# nrf7140_sysctrl register map
Vendor: Nordic Semiconductor; Series: nRF71; File version: 1
Registers are 32-bit, read-write, reset 0x0 unless marked. A register's access mark holds for its fields unless they carry their own. Offsets are from the block's base; [hi:lo] are bit positions; lines under a group give offsets from that group; {n}, {i} and the like mark numbered series.

## PPIB110 — PPIB APB registers 0
Base 0x5F098000
Same registers: PPIB120 0x5F8EE000, PPIB121 0x5F8EF000, PPIB130 0x5F925000, PPIB131 0x5F926000, PPIB132 0x5F98D000, PPIB133 0x5F99D000, PPIB134 0x5F9AD000, PPIB135 0x5F9BD000, PPIB136 0x5F9CD000, PPIB137 0x5F9DD000
{0x0+4i} TASKS_SEND[{i}] (i=0..31) wo — Description collection: This task is unused, but the PPIB provides the SUBSCRIBE task to connect SEND [n] task.
  [0] TASKS_SEND — This task is unused, but the PPIB provides the SUBSCRIBE task to connect SEND [n] task.
    1=Trigger task
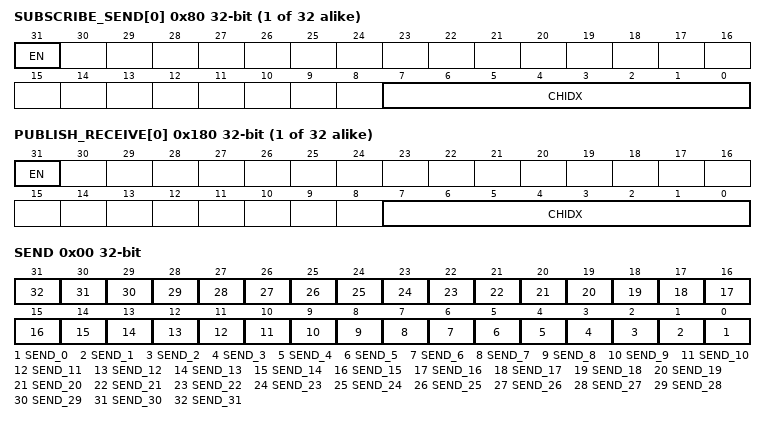
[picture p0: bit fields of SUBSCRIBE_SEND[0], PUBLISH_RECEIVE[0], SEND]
{0x80+4i} SUBSCRIBE_SEND[{i}] (i=0..31) — Description collection: Subscribe configuration for task SEND[n]
  [31] EN
    0=Disabled (Disable subscription); 1=Enabled (Enable subscription)
  [7:0] CHIDX — DPPI channel that task SEND[n] will subscribe to
{0x100+4i} EVENTS_RECEIVE[{i}] (i=0..31) — Description collection: This event is unused, but the PPIB provides the PUBLISH event to connect RECEIVE [n] event.
  [0] EVENTS_RECEIVE — This event is unused, but the PPIB provides the PUBLISH event to connect RECEIVE [n] event.
    0=NotGenerated (Event not generated); 1=Generated (Event generated)
{0x180+4i} PUBLISH_RECEIVE[{i}] (i=0..31) — Description collection: Publish configuration for event RECEIVE[n]
  [31] EN
    0=Disabled (Disable publishing); 1=Enabled (Enable publishing)
  [7:0] CHIDX — DPPI channel that event RECEIVE[n] will publish to
0x400 OVERFLOW group — Unspecified
  0x00 SEND — The task overflow for SEND tasks using SUBSCRIBE_SEND. Write 0 to clear.
    [all] fields
      1=Overflow (Task overflow is happened.); 0=NoOverflow (Task overflow is not happened.)
    [n] SEND_{n} (n=0..31) — The status for tasks overflow at SUBSCRIBE_SEND[{n}].

## ROMC — ROM Controller
Base 0x5F8C6000
0x500 POWER group — Unspecified
  0x00 CONTROL reset 0x1 — ROM power control register.
    [0] MEM0 — Keep the ROM block MEM[0] on or off when in System ON mode.
      0=Off (Power down); 1=On (Power up)

## GLOBAL_MUTEX120 — MUTEX 0
Base 0x4F8D2000
Same registers: GLOBAL_MUTEX130 0x4F927000
{0x400+4i} MUTEX[{i}] (i=0..31) — Description collection: Mutex register
  [0] MUTEX — Mutex register n
    0=Unlocked (Mutex n is in unlocked state); 1=Locked (Mutex n is in locked state)

## GLOBAL_PROTOTYPE — Prototype HW information registers.
Base 0x4F8D2000; alternate view of GLOBAL_MUTEX120
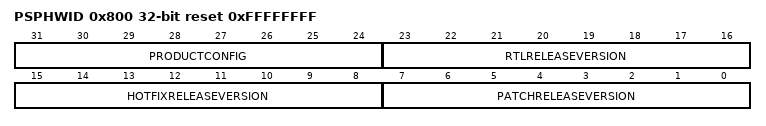
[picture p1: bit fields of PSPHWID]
0x800 PSPHWID ro reset 0xFFFFFFFF — PSP hardware ID register, unique ID for each prototype release. Used to identify RTL release that prototype is based on.
  [31:24] PRODUCTCONFIG
  [23:16] RTLRELEASEVERSION — First letter of RTL release version in ASCII corresponding to A-Z.
  [15:8] HOTFIXRELEASEVERSION
  [7:0] PATCHRELEASEVERSION — PSP patch/bugfix release version
0x804 FPGATIMESTAMP ro — 32-bit timestamp value stored by the FPGA bitstream in format ddddd_MMMM_yyyyyy_hhhhh_mmmmmm_ssssss. Unique for every FPGA netlist implementation, not dependent to RTL synthesis. 0x87654321 set in emulator database.
  [31:0] FPGATIMESTAMP — ddddd = 5 bits to represent 31 days in a month. MMMM = 4 bits to represent 12 months in a year. yyyyyy = 6 bits to represent 0 to 63 (to note year 2000 to 2063). hhhhh = 5 bits to represent 24 hours in a day. mmmmmm = 6 bits to represent 60 minutes in an hour. ssssss = 6 bits to represent 60 seconds in a minute.
0x808 EMULATORSPEEDVALUE ro — Used to store real speed of emulator is running. Used by SW to config UART speed etc, to ensure correct operation.
  [31:0] EMULATORSPEEDVALUE — Actual clock speed for FCLK 400M in emulator (Hz). In FPGA set to 0x0.
0x80C FPGACLOCKDIVIDERRATIO ro — Overall clock divider ratio for FPGA
  [31:0] FPGACLOCKDIVIDERRATIO — Overall clock divider ratio for FPGA. Set to 0 for emulator database.

## Notices in the file
Copyright (c) 2010 - 2024, Nordic Semiconductor ASA
All rights reserved.
Redistribution and use in source and binary forms, with or without modification,
are permitted provided that the following conditions are met:
1. Redistributions of source code must retain the above copyright notice, this
list of conditions and the following disclaimer.
2. Redistributions in binary form, except as embedded into a Nordic
Semiconductor ASA integrated circuit in a product or a software update for
such product, must reproduce the above copyright notice, this list of
conditions and the following disclaimer in the documentation and/or other
materials provided with the distribution.
3. Neither the name of Nordic Semiconductor ASA nor the names of its
contributors may be used to endorse or promote products derived from this
software without specific prior written permission.
4. This software, with or without modification, must only be used with a
Nordic Semiconductor ASA integrated circuit.
5. Any software provided in binary form under this license must not be reverse
engineered, decompiled, modified and/or disassembled.
THIS SOFTWARE IS PROVIDED BY NORDIC SEMICONDUCTOR ASA "AS IS" AND ANY EXPRESS
OR IMPLIED WARRANTIES, INCLUDING, BUT NOT LIMITED TO, THE IMPLIED WARRANTIES
OF MERCHANTABILITY, NONINFRINGEMENT, AND FITNESS FOR A PARTICULAR PURPOSE ARE
DISCLAIMED. IN NO EVENT SHALL NORDIC SEMICONDUCTOR ASA OR CONTRIBUTORS BE
LIABLE FOR ANY DIRECT, INDIRECT, INCIDENTAL, SPECIAL, EXEMPLARY, OR
CONSEQUENTIAL DAMAGES (INCLUDING, BUT NOT LIMITED TO, PROCUREMENT OF SUBSTITUTE
GOODS OR SERVICES; LOSS OF USE, DATA, OR PROFITS; OR BUSINESS INTERRUPTION)
HOWEVER CAUSED AND ON ANY THEORY OF LIABILITY, WHETHER IN CONTRACT, STRICT
LIABILITY, OR TORT (INCLUDING NEGLIGENCE OR OTHERWISE) ARISING IN ANY WAY OUT
OF THE USE OF THIS SOFTWARE, EVEN IF ADVISED OF THE POSSIBILITY OF SUCH DAMAGE.
